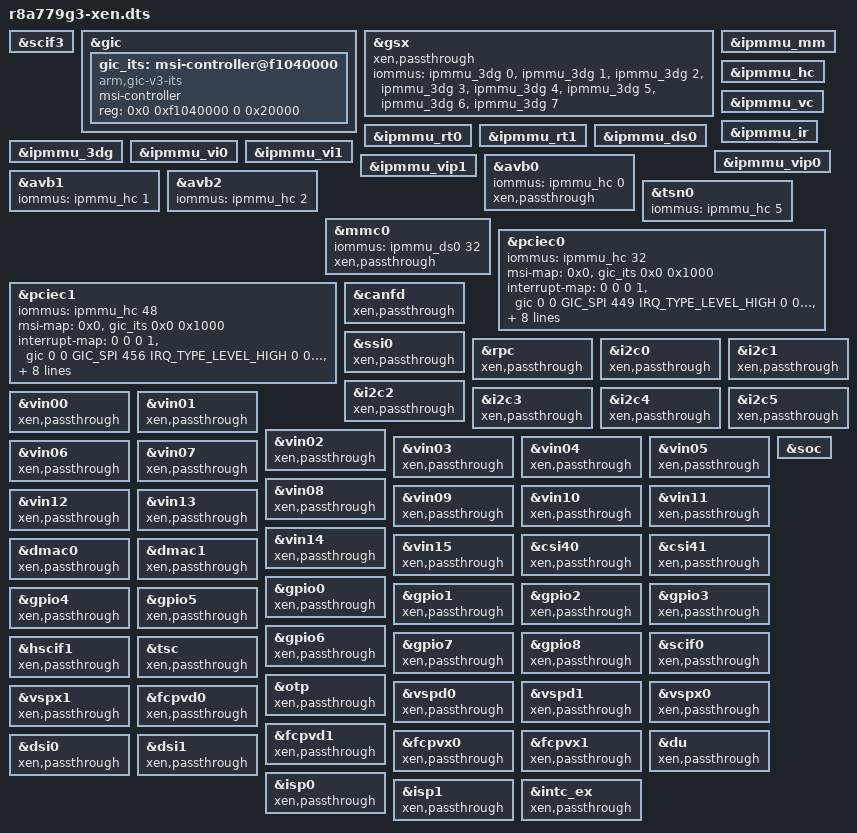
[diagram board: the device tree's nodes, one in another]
/* Make sure Xen console is enabled. */
&scif3	{
	status = "okay";
};

&gic {
	#address-cells = <2>;
	#size-cells = <2>;
	ranges;

	gic_its: msi-controller@f1040000 {
		compatible = "arm,gic-v3-its";
		msi-controller;
		#msi-cells = <1>;
		reg = <0x0 0xf1040000 0 0x20000>;
	};
};

&gsx {
	xen,passthrough;
	iommus = <&ipmmu_3dg 0>, <&ipmmu_3dg 1>,
		<&ipmmu_3dg 2>, <&ipmmu_3dg 3>,
		<&ipmmu_3dg 4>, <&ipmmu_3dg 5>,
		<&ipmmu_3dg 6>, <&ipmmu_3dg 7>;
};

&ipmmu_mm {
	status = "okay";
};
&ipmmu_hc {
	status = "okay";
};
&ipmmu_vc {
	status = "okay";
};
&ipmmu_ir {
	status = "okay";
};

&ipmmu_rt0 {
	status = "okay";
};
&ipmmu_rt1 {
	status = "okay";
};
&ipmmu_ds0{
	status = "okay";
};
&ipmmu_3dg{
	status = "okay";
};
&ipmmu_vi0{
	status = "okay";
};
&ipmmu_vi1{
	status = "okay";
};
&ipmmu_vip0{
	status = "okay";
};
&ipmmu_vip1{
	status = "okay";
};

&avb0 {
	iommus = <&ipmmu_hc 0>;
};

&avb1 {
	iommus = <&ipmmu_hc 1>;
};

&avb2 {
	iommus = <&ipmmu_hc 2>;
};

&tsn0 {
	iommus = <&ipmmu_hc 5>;
};

&mmc0 {
	iommus = <&ipmmu_ds0 32>;
};

&pciec0 {
	iommus = <&ipmmu_hc 32>;
	msi-map = <0x0 &gic_its 0x0 0x1000>;
	interrupt-map = <0 0 0 1 &gic 0 0 GIC_SPI 449 IRQ_TYPE_LEVEL_HIGH
					0 0 0 2 &gic 0 0 GIC_SPI 449 IRQ_TYPE_LEVEL_HIGH
					0 0 0 3 &gic 0 0 GIC_SPI 449 IRQ_TYPE_LEVEL_HIGH
					0 0 0 4 &gic 0 0 GIC_SPI 449 IRQ_TYPE_LEVEL_HIGH>;
	iommu-map = <0x000 &ipmmu_hc 32 0x1>,
		    <0x100 &ipmmu_hc 33 0x1>,
		    <0x101 &ipmmu_hc 34 0x1>,
		    <0x102 &ipmmu_hc 35 0x10>,
		    <0x280 &ipmmu_hc 36 0x1>;
};

&pciec1 {
	iommus = <&ipmmu_hc 48>;
	msi-map = <0x0 &gic_its 0x0 0x1000>;
	interrupt-map = <0 0 0 1 &gic 0 0 GIC_SPI 456 IRQ_TYPE_LEVEL_HIGH
					0 0 0 2 &gic 0 0 GIC_SPI 456 IRQ_TYPE_LEVEL_HIGH
					0 0 0 3 &gic 0 0 GIC_SPI 456 IRQ_TYPE_LEVEL_HIGH
					0 0 0 4 &gic 0 0 GIC_SPI 456 IRQ_TYPE_LEVEL_HIGH>;
	iommu-map = <0x000 &ipmmu_hc 48 0x1>,
		    <0x100 &ipmmu_hc 49 0x1>,
		    <0x101 &ipmmu_hc 50 0x1>,
		    <0x102 &ipmmu_hc 51 0x10>,
		    <0x280 &ipmmu_hc 52 0x1>;
};

/delete-node/ &pciec0_ep;
/delete-node/ &pciec1_ep;

&avb0		{ xen,passthrough; };
&canfd		{ xen,passthrough; };
&ssi0		{ xen,passthrough; };
&rpc		{ xen,passthrough; };
&i2c0		{ xen,passthrough; };
&i2c1		{ xen,passthrough; };
&i2c2		{ xen,passthrough; };
&i2c3		{ xen,passthrough; };
&i2c4		{ xen,passthrough; };
&i2c5		{ xen,passthrough; };
&vin00		{ xen,passthrough; };
&vin01		{ xen,passthrough; };
&vin02		{ xen,passthrough; };
&vin03		{ xen,passthrough; };
&vin04		{ xen,passthrough; };
&vin05		{ xen,passthrough; };
&vin06		{ xen,passthrough; };
&vin07		{ xen,passthrough; };
&vin08		{ xen,passthrough; };
&vin09		{ xen,passthrough; };
&vin10		{ xen,passthrough; };
&vin11		{ xen,passthrough; };
&vin12		{ xen,passthrough; };
&vin13		{ xen,passthrough; };
&vin14		{ xen,passthrough; };
&vin15		{ xen,passthrough; };
&csi40		{ xen,passthrough; };
&csi41		{ xen,passthrough; };
&dmac0		{ xen,passthrough; };
&dmac1		{ xen,passthrough; };
&gpio0		{ xen,passthrough; };
&gpio1		{ xen,passthrough; };
&gpio2		{ xen,passthrough; };
&gpio3		{ xen,passthrough; };
&gpio4		{ xen,passthrough; };
&gpio5		{ xen,passthrough; };
&gpio6		{ xen,passthrough; };
&gpio7		{ xen,passthrough; };
&gpio8		{ xen,passthrough; };
&i2c4		{ xen,passthrough; };
&mmc0		{ xen,passthrough; };
&pciec0		{ xen,passthrough; };
&pciec1		{ xen,passthrough; };
&scif0		{ xen,passthrough; };
&hscif1		{ xen,passthrough; };
&tsc		{ xen,passthrough; };
&otp		{ xen,passthrough; };
&vspd0		{ xen,passthrough; };
&vspd1		{ xen,passthrough; };
&vspx0		{ xen,passthrough; };
&vspx1		{ xen,passthrough; };
&fcpvd0		{ xen,passthrough; };
&fcpvd1		{ xen,passthrough; };
&fcpvx0		{ xen,passthrough; };
&fcpvx1		{ xen,passthrough; };
&du		{ xen,passthrough; };
&dsi0		{ xen,passthrough; };
&dsi1		{ xen,passthrough; };
&isp0		{ xen,passthrough; };
&isp1		{ xen,passthrough; };
&intc_ex	{ xen,passthrough; };

&soc {
};
